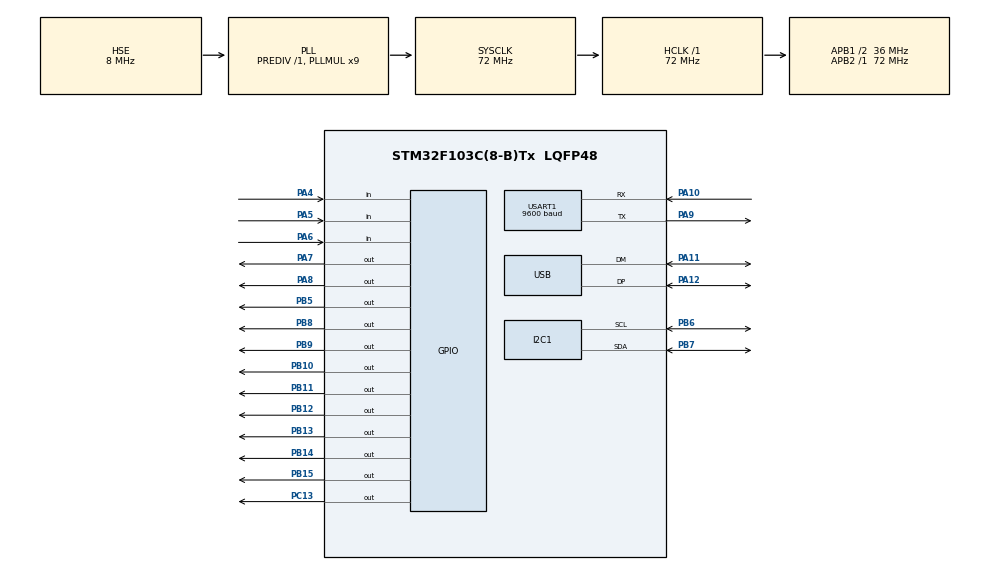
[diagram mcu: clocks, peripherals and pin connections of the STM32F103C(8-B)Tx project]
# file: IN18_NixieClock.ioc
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FREERTOS.Tasks01=defaultTask,0,128,StartDefaultTask,Default,NULL
FREERTOS.configMINIMAL_STACK_SIZE=64
FREERTOS.configTOTAL_HEAP_SIZE=5120
Mcu.Family=STM32F1
Mcu.Name=STM32F103C(8-B)Tx
Mcu.Package=LQFP48
NVIC.PriorityGroup=NVIC_PRIORITYGROUP_4
NVIC.TIM1_UP_IRQn=true\:0\:0\:false\:false\:true\:false\:false
NVIC.TimeBase=TIM1_UP_IRQn
NVIC.TimeBaseIP=TIM1
NVIC.USB_LP_CAN1_RX0_IRQn=true\:5\:0\:false\:false\:true\:true\:false
PA10.Mode=Asynchronous
PA10.Signal=USART1_RX
PA11.Mode=Device
PA11.Signal=USB_DM
PA12.Mode=Device
PA12.Signal=USB_DP
PA13.Mode=Serial_Wire
PA13.Signal=SYS_JTMS-SWDIO
PA14.Mode=Serial_Wire
PA14.Signal=SYS_JTCK-SWCLK
PA4.GPIO_Mode=GPIO_MODE_INPUT
PA4.GPIO_PuPd=GPIO_NOPULL
PA4.Signal=GPIO_Input
PA5.GPIO_Mode=GPIO_MODE_INPUT
PA5.GPIO_PuPd=GPIO_NOPULL
PA5.Signal=GPIO_Input
PA6.GPIO_Mode=GPIO_MODE_INPUT
PA6.GPIO_PuPd=GPIO_NOPULL
PA6.Signal=GPIO_Input
PA7.Signal=GPIO_Output
PA8.Signal=GPIO_Output
PA9.Mode=Asynchronous
PA9.Signal=USART1_TX
PB10.GPIO_Speed=GPIO_SPEED_FREQ_HIGH
PB10.Signal=GPIO_Output
PB11.GPIO_Speed=GPIO_SPEED_FREQ_HIGH
PB11.Signal=GPIO_Output
PB12.GPIO_Speed=GPIO_SPEED_FREQ_HIGH
PB12.Signal=GPIO_Output
PB13.GPIO_Speed=GPIO_SPEED_FREQ_HIGH
PB13.Signal=GPIO_Output
PB14.GPIO_Speed=GPIO_SPEED_FREQ_HIGH
PB14.Signal=GPIO_Output
PB15.GPIO_Speed=GPIO_SPEED_FREQ_HIGH
PB15.Signal=GPIO_Output
PB5.Signal=GPIO_Output
PB6.Mode=I2C
PB6.Signal=I2C1_SCL
PB7.Mode=I2C
PB7.Signal=I2C1_SDA
PB8.Signal=GPIO_Output
PB9.Signal=GPIO_Output
PC13-TAMPER-RTC.Signal=GPIO_Output
PC14-OSC32_IN.Mode=LSE-External-Oscillator
PC14-OSC32_IN.Signal=RCC_OSC32_IN
PC15-OSC32_OUT.Mode=LSE-External-Oscillator
PC15-OSC32_OUT.Signal=RCC_OSC32_OUT
PD0-OSC_IN.Mode=HSE-External-Oscillator
PD0-OSC_IN.Signal=RCC_OSC_IN
PD1-OSC_OUT.Mode=HSE-External-Oscillator
PD1-OSC_OUT.Signal=RCC_OSC_OUT
ProjectManager.HeapSize=0x200
ProjectManager.StackSize=0x400
ProjectManager.TargetToolchain=SW4STM32
RCC.AHBFreq_Value=72000000
RCC.APB1CLKDivider=RCC_HCLK_DIV2
RCC.APB1Freq_Value=36000000
RCC.APB1TimFreq_Value=72000000
RCC.APB2Freq_Value=72000000
RCC.APB2TimFreq_Value=72000000
RCC.HCLKFreq_Value=72000000
RCC.PLLMUL=RCC_PLL_MUL9
RCC.PLLSourceVirtual=RCC_PLLSOURCE_HSE
RCC.SYSCLKFreq_VALUE=72000000
RCC.SYSCLKSource=RCC_SYSCLKSOURCE_PLLCLK
RCC.USBFreq_Value=48000000
RCC.USBPrescaler=RCC_USBCLKSOURCE_PLL_DIV1_5
USART1.BaudRate=9600
USART1.VirtualMode=VM_ASYNC
USB_DEVICE.CLASS_NAME_FS=CDC
USB_DEVICE.VirtualMode=Cdc
USB_DEVICE.VirtualModeFS=Cdc_FS
VP_FREERTOS_VS_ENABLE.Mode=Enabled
VP_RTC_VS_RTC_Activate.Mode=RTC_Enabled
VP_SYS_VS_tim1.Mode=TIM1
VP_USB_DEVICE_VS_USB_DEVICE_CDC_FS.Mode=CDC_FS
board=IN18_NixieClock

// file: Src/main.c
/**
  ******************************************************************************
  * @file           : main.c
  * @brief          : Main program body
  ******************************************************************************
  * This notice applies to any and all portions of this file
  * that are not between comment pairs USER CODE BEGIN and
  * USER CODE END. Other portions of this file, whether
  * inserted by the user or by software development tools
  * are owned by their respective copyright owners.
  *
  * Copyright (c) 2018 STMicroelectronics International N.V.
  * All rights reserved.
  *
  * Redistribution and use in source and binary forms, with or without
  * modification, are permitted, provided that the following conditions are met:
  *
  * 1. Redistribution of source code must retain the above copyright notice,
  *    this list of conditions and the following disclaimer.
  * 2. Redistributions in binary form must reproduce the above copyright notice,
  *    this list of conditions and the following disclaimer in the documentation
  *    and/or other materials provided with the distribution.
  * 3. Neither the name of STMicroelectronics nor the names of other
  *    contributors to this software may be used to endorse or promote products
  *    derived from this software without specific written permission.
  * 4. This software, including modifications and/or derivative works of this
  *    software, must execute solely and exclusively on microcontroller or
  *    microprocessor devices manufactured by or for STMicroelectronics.
  * 5. Redistribution and use of this software other than as permitted under
  *    this license is void and will automatically terminate your rights under
  *    this license.
  *
  * THIS SOFTWARE IS PROVIDED BY STMICROELECTRONICS AND CONTRIBUTORS "AS IS"
  * AND ANY EXPRESS, IMPLIED OR STATUTORY WARRANTIES, INCLUDING, BUT NOT
  * LIMITED TO, THE IMPLIED WARRANTIES OF MERCHANTABILITY, FITNESS FOR A
  * PARTICULAR PURPOSE AND NON-INFRINGEMENT OF THIRD PARTY INTELLECTUAL PROPERTY
  * RIGHTS ARE DISCLAIMED TO THE FULLEST EXTENT PERMITTED BY LAW. IN NO EVENT
  * SHALL STMICROELECTRONICS OR CONTRIBUTORS BE LIABLE FOR ANY DIRECT, INDIRECT,
  * INCIDENTAL, SPECIAL, EXEMPLARY, OR CONSEQUENTIAL DAMAGES (INCLUDING, BUT NOT
  * LIMITED TO, PROCUREMENT OF SUBSTITUTE GOODS OR SERVICES; LOSS OF USE, DATA,
  * OR PROFITS; OR BUSINESS INTERRUPTION) HOWEVER CAUSED AND ON ANY THEORY OF
  * LIABILITY, WHETHER IN CONTRACT, STRICT LIABILITY, OR TORT (INCLUDING
  * NEGLIGENCE OR OTHERWISE) ARISING IN ANY WAY OUT OF THE USE OF THIS SOFTWARE,
  * EVEN IF ADVISED OF THE POSSIBILITY OF SUCH DAMAGE.
  *
  ******************************************************************************
  */
#include <ds3231.h>
#include "main.h"
#include "stm32f1xx_hal.h"
#include "cmsis_os.h"
#include "usb_device.h"

/* USER CODE BEGIN Includes */
#include "nixieclock.h"
#include "pins.h"
#include "clockState.h"
/* USER CODE END Includes */

I2C_HandleTypeDef hi2c1;

RTC_HandleTypeDef hrtc;

UART_HandleTypeDef huart1;

osThreadId defaultTaskHandle;

/* USER CODE BEGIN PV */
/* Private variables ---------------------------------------------------------*/

/* USER CODE END PV */

void SystemClock_Config(void);
static void MX_GPIO_Init(void);
static void MX_USART1_UART_Init(void);
static void MX_I2C1_Init(void);
static void MX_RTC_Init(void);
void StartDefaultTask(void const * argument);

/* USER CODE BEGIN PFP */
/* Private function prototypes -----------------------------------------------*/

/* USER CODE END PFP */

int main(void)
{

  /* MCU Configuration----------------------------------------------------------*/

  /* Reset of all peripherals, Initializes the Flash interface and the Systick. */
  HAL_Init();

  /* Configure the system clock */
  SystemClock_Config();

  /* Initialize all configured peripherals */
  MX_GPIO_Init();
  MX_USART1_UART_Init();
  MX_I2C1_Init();
  MX_RTC_Init();

  /* Create the thread(s) */
  /* definition and creation of defaultTask */
  osThreadDef(defaultTask, StartDefaultTask, osPriorityNormal, 0, 128);
  defaultTaskHandle = osThreadCreate(osThread(defaultTask), NULL);

  /* USER CODE BEGIN RTOS_THREADS */
    osThreadDef(miscLoopTask, miscLoop, osPriorityAboveNormal, 0, 64);
    osThreadCreate(osThread(miscLoopTask), NULL);

    // Clock Render Thread
    osThreadDef(clockRenderTask, clockRenderLoop, osPriorityAboveNormal, 0, 64);
    osThreadCreate(osThread(clockRenderTask), NULL);

    // Clock Mechanism Logic Control
    osThreadDef(clockMechanism, clockMechanismLoop, osPriorityNormal, 0, 128);
    osThreadCreate(osThread(clockMechanism), NULL);
  /* USER CODE END RTOS_THREADS */

  /* USER CODE BEGIN RTOS_QUEUES */
    /* add queues, ... */

    renderQueueHandle = xQueueCreate(4, sizeof(char *));
    buttonPressHandle = xQueueCreate(4, sizeof(struct buttonAction));
  /* USER CODE END RTOS_QUEUES */
    RTC_init();

  /* Start scheduler */
  osKernelStart();

  /* We should never get here as control is now taken by the scheduler */

  /* Infinite loop */
    while (1) {

    }

}

void SystemClock_Config(void)
{

  RCC_OscInitTypeDef RCC_OscInitStruct;
  RCC_ClkInitTypeDef RCC_ClkInitStruct;
  RCC_PeriphCLKInitTypeDef PeriphClkInit;

    /**Initializes the CPU, AHB and APB busses clocks
    */
  RCC_OscInitStruct.OscillatorType = RCC_OSCILLATORTYPE_LSI|RCC_OSCILLATORTYPE_HSE;
  RCC_OscInitStruct.HSEState = RCC_HSE_ON;
  RCC_OscInitStruct.HSEPredivValue = RCC_HSE_PREDIV_DIV1;
  RCC_OscInitStruct.HSIState = RCC_HSI_ON;
  RCC_OscInitStruct.LSIState = RCC_LSI_ON;
  RCC_OscInitStruct.PLL.PLLState = RCC_PLL_ON;
  RCC_OscInitStruct.PLL.PLLSource = RCC_PLLSOURCE_HSE;
  RCC_OscInitStruct.PLL.PLLMUL = RCC_PLL_MUL9;
  if (HAL_RCC_OscConfig(&RCC_OscInitStruct) != HAL_OK)
  {
    _Error_Handler(__FILE__, __LINE__);
  }

    /**Initializes the CPU, AHB and APB busses clocks
    */
  RCC_ClkInitStruct.ClockType = RCC_CLOCKTYPE_HCLK|RCC_CLOCKTYPE_SYSCLK
                              |RCC_CLOCKTYPE_PCLK1|RCC_CLOCKTYPE_PCLK2;
  RCC_ClkInitStruct.SYSCLKSource = RCC_SYSCLKSOURCE_PLLCLK;
  RCC_ClkInitStruct.AHBCLKDivider = RCC_SYSCLK_DIV1;
  RCC_ClkInitStruct.APB1CLKDivider = RCC_HCLK_DIV2;
  RCC_ClkInitStruct.APB2CLKDivider = RCC_HCLK_DIV1;

  if (HAL_RCC_ClockConfig(&RCC_ClkInitStruct, FLASH_LATENCY_2) != HAL_OK)
  {
    _Error_Handler(__FILE__, __LINE__);
  }

  PeriphClkInit.PeriphClockSelection = RCC_PERIPHCLK_RTC|RCC_PERIPHCLK_USB;
  PeriphClkInit.RTCClockSelection = RCC_RTCCLKSOURCE_LSI;
  PeriphClkInit.UsbClockSelection = RCC_USBCLKSOURCE_PLL_DIV1_5;
  if (HAL_RCCEx_PeriphCLKConfig(&PeriphClkInit) != HAL_OK)
  {
    _Error_Handler(__FILE__, __LINE__);
  }

    /**Configure the Systick interrupt time
    */
  HAL_SYSTICK_Config(HAL_RCC_GetHCLKFreq()/1000);

    /**Configure the Systick
    */
  HAL_SYSTICK_CLKSourceConfig(SYSTICK_CLKSOURCE_HCLK);

  /* SysTick_IRQn interrupt configuration */
  HAL_NVIC_SetPriority(SysTick_IRQn, 15, 0);
}

/* I2C1 init function */
static void MX_I2C1_Init(void)
{

  hi2c1.Instance = I2C1;
  hi2c1.Init.ClockSpeed = 100000;
  hi2c1.Init.DutyCycle = I2C_DUTYCYCLE_2;
  hi2c1.Init.OwnAddress1 = 0;
  hi2c1.Init.AddressingMode = I2C_ADDRESSINGMODE_7BIT;
  hi2c1.Init.DualAddressMode = I2C_DUALADDRESS_DISABLE;
  hi2c1.Init.OwnAddress2 = 0;
  hi2c1.Init.GeneralCallMode = I2C_GENERALCALL_DISABLE;
  hi2c1.Init.NoStretchMode = I2C_NOSTRETCH_DISABLE;
  if (HAL_I2C_Init(&hi2c1) != HAL_OK)
  {
    _Error_Handler(__FILE__, __LINE__);
  }

}

/* RTC init function */
static void MX_RTC_Init(void)
{

    /**Initialize RTC Only
    */
  hrtc.Instance = RTC;
  hrtc.Init.AsynchPrediv = RTC_AUTO_1_SECOND;
  hrtc.Init.OutPut = RTC_OUTPUTSOURCE_ALARM;
  if (HAL_RTC_Init(&hrtc) != HAL_OK)
  {
    _Error_Handler(__FILE__, __LINE__);
  }

}

/* USART1 init function */
static void MX_USART1_UART_Init(void)
{

  huart1.Instance = USART1;
  huart1.Init.BaudRate = 9600;
  huart1.Init.WordLength = UART_WORDLENGTH_8B;
  huart1.Init.StopBits = UART_STOPBITS_1;
  huart1.Init.Parity = UART_PARITY_NONE;
  huart1.Init.Mode = UART_MODE_TX_RX;
  huart1.Init.HwFlowCtl = UART_HWCONTROL_NONE;
  huart1.Init.OverSampling = UART_OVERSAMPLING_16;
  if (HAL_UART_Init(&huart1) != HAL_OK)
  {
    _Error_Handler(__FILE__, __LINE__);
  }

}

/** Configure pins as
        * Analog
        * Input
        * Output
        * EVENT_OUT
        * EXTI
*/
static void MX_GPIO_Init(void)
{

  GPIO_InitTypeDef GPIO_InitStruct;

  /* GPIO Ports Clock Enable */
  __HAL_RCC_GPIOC_CLK_ENABLE();
  __HAL_RCC_GPIOD_CLK_ENABLE();
  __HAL_RCC_GPIOA_CLK_ENABLE();
  __HAL_RCC_GPIOB_CLK_ENABLE();

  /*Configure GPIO pin Output Level */
  HAL_GPIO_WritePin(GPIOC, GPIO_PIN_13, GPIO_PIN_RESET);

  /*Configure GPIO pin Output Level */
  HAL_GPIO_WritePin(GPIOA, GPIO_PIN_7|GPIO_PIN_8, GPIO_PIN_RESET);

  /*Configure GPIO pin Output Level */
  HAL_GPIO_WritePin(GPIOB, GPIO_PIN_10|GPIO_PIN_11|GPIO_PIN_12|GPIO_PIN_13
                          |GPIO_PIN_14|GPIO_PIN_15|GPIO_PIN_5|GPIO_PIN_8
                          |GPIO_PIN_9, GPIO_PIN_RESET);

  /*Configure GPIO pin : PC13 */
  GPIO_InitStruct.Pin = GPIO_PIN_13;
  GPIO_InitStruct.Mode = GPIO_MODE_OUTPUT_PP;
  GPIO_InitStruct.Speed = GPIO_SPEED_FREQ_LOW;
  HAL_GPIO_Init(GPIOC, &GPIO_InitStruct);

  /*Configure GPIO pins : PA4 PA5 PA6 */
  GPIO_InitStruct.Pin = GPIO_PIN_4|GPIO_PIN_5|GPIO_PIN_6;
  GPIO_InitStruct.Mode = GPIO_MODE_INPUT;
  GPIO_InitStruct.Pull = GPIO_NOPULL;
  HAL_GPIO_Init(GPIOA, &GPIO_InitStruct);

  /*Configure GPIO pins : PA7 PA8 */
  GPIO_InitStruct.Pin = GPIO_PIN_7|GPIO_PIN_8;
  GPIO_InitStruct.Mode = GPIO_MODE_OUTPUT_PP;
  GPIO_InitStruct.Speed = GPIO_SPEED_FREQ_LOW;
  HAL_GPIO_Init(GPIOA, &GPIO_InitStruct);

  /*Configure GPIO pins : PB10 PB11 PB12 PB13
                           PB14 PB15 */
  GPIO_InitStruct.Pin = GPIO_PIN_10|GPIO_PIN_11|GPIO_PIN_12|GPIO_PIN_13
                          |GPIO_PIN_14|GPIO_PIN_15;
  GPIO_InitStruct.Mode = GPIO_MODE_OUTPUT_PP;
  GPIO_InitStruct.Speed = GPIO_SPEED_FREQ_HIGH;
  HAL_GPIO_Init(GPIOB, &GPIO_InitStruct);

  /*Configure GPIO pins : PB5 PB8 PB9 */
  GPIO_InitStruct.Pin = GPIO_PIN_5|GPIO_PIN_8|GPIO_PIN_9;
  GPIO_InitStruct.Mode = GPIO_MODE_OUTPUT_PP;
  GPIO_InitStruct.Speed = GPIO_SPEED_FREQ_LOW;
  HAL_GPIO_Init(GPIOB, &GPIO_InitStruct);

}

/* StartDefaultTask function */
void StartDefaultTask(void const * argument)
{
  /* init code for USB_DEVICE */
  MX_USB_DEVICE_Init();

  /* USER CODE BEGIN 5 */
    /* Infinite loop */
    for (;;) {
        osDelay(1000);
    }
  /* USER CODE END 5 */
}

void HAL_TIM_PeriodElapsedCallback(TIM_HandleTypeDef *htim)
{
  if (htim->Instance == TIM1) {
    HAL_IncTick();
  }
}

void _Error_Handler(char *file, int line)
{
    while (1) {
    }
}

/************************ (C) COPYRIGHT STMicroelectronics *****END OF FILE****/
